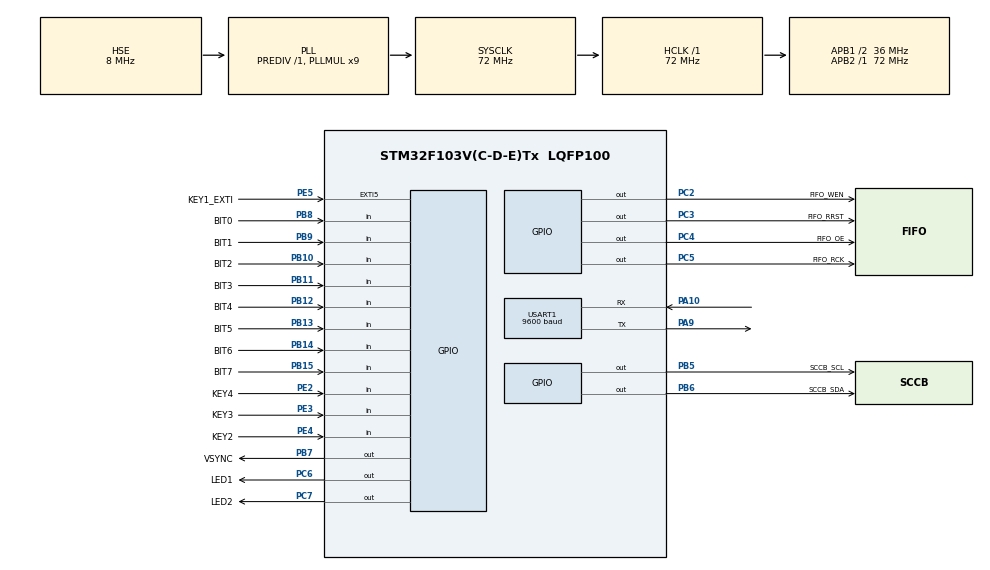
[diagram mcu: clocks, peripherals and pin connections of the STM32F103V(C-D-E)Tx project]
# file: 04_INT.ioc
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Mcu.Family=STM32F1
Mcu.Name=STM32F103V(C-D-E)Tx
Mcu.Package=LQFP100
NVIC.EXTI9_5_IRQn=true\:1\:0\:true\:false\:true\:true
NVIC.PriorityGroup=NVIC_PRIORITYGROUP_4
OSC_IN.Mode=HSE-External-Oscillator
OSC_IN.Signal=RCC_OSC_IN
OSC_OUT.Mode=HSE-External-Oscillator
OSC_OUT.Signal=RCC_OSC_OUT
PA10.Mode=Asynchronous
PA10.Signal=USART1_RX
PA9.Mode=Asynchronous
PA9.Signal=USART1_TX
PB10.GPIO_Label=BIT2
PB10.Signal=GPIO_Input
PB11.GPIO_Label=BIT3
PB11.Signal=GPIO_Input
PB12.GPIO_Label=BIT4
PB12.Signal=GPIO_Input
PB13.GPIO_Label=BIT5
PB13.Signal=GPIO_Input
PB14.GPIO_Label=BIT6
PB14.Signal=GPIO_Input
PB15.GPIO_Label=BIT7
PB15.Signal=GPIO_Input
PB5.GPIO_Label=SCCB_SCL
PB5.GPIO_PuPd=GPIO_PULLUP
PB5.GPIO_Speed=GPIO_SPEED_FREQ_HIGH
PB5.PinState=GPIO_PIN_SET
PB5.Signal=GPIO_Output
PB6.GPIO_Label=SCCB_SDA
PB6.GPIO_PuPd=GPIO_PULLUP
PB6.GPIO_Speed=GPIO_SPEED_FREQ_HIGH
PB6.PinState=GPIO_PIN_SET
PB6.Signal=GPIO_Output
PB7.GPIO_Label=VSYNC
PB7.GPIO_Speed=GPIO_SPEED_FREQ_HIGH
PB7.Signal=GPIO_Output
PB8.GPIO_Label=BIT0
PB8.Signal=GPIO_Input
PB9.GPIO_Label=BIT1
PB9.Signal=GPIO_Input
PC2.GPIO_Label=FIFO_WEN
PC2.GPIO_Speed=GPIO_SPEED_FREQ_HIGH
PC2.Signal=GPIO_Output
PC3.GPIO_Label=FIFO_RRST
PC3.Signal=GPIO_Output
PC4.GPIO_Label=FIFO_OE
PC4.GPIO_Speed=GPIO_SPEED_FREQ_HIGH
PC4.Signal=GPIO_Output
PC5.GPIO_Label=FIFO_RCK
PC5.GPIO_Speed=GPIO_SPEED_FREQ_HIGH
PC5.Signal=GPIO_Output
PC6.GPIO_Label=LED1
PC6.GPIO_Speed=GPIO_SPEED_FREQ_HIGH
PC6.Signal=GPIO_Output
PC7.GPIO_Label=LED2
PC7.GPIO_ModeDefaultOutputPP=GPIO_MODE_OUTPUT_PP
PC7.GPIO_Speed=GPIO_SPEED_FREQ_HIGH
PC7.Signal=GPIO_Output
PE2.GPIO_Label=KEY4
PE2.Signal=GPIO_Input
PE3.GPIO_Label=KEY3
PE3.Signal=GPIO_Input
PE4.GPIO_Label=KEY2
PE4.Signal=GPIO_Input
PE5.GPIO_Label=KEY1_EXTI
PE5.GPIO_ModeDefaultEXTI=GPIO_MODE_IT_FALLING
PE5.Signal=GPXTI5
ProjectManager.HeapSize=0x200
ProjectManager.StackSize=0x400
ProjectManager.TargetToolchain=SW4STM32
RCC.AHBFreq_Value=72000000
RCC.APB1CLKDivider=RCC_HCLK_DIV2
RCC.APB1Freq_Value=36000000
RCC.APB1TimFreq_Value=72000000
RCC.APB2Freq_Value=72000000
RCC.APB2TimFreq_Value=72000000
RCC.HCLKFreq_Value=72000000
RCC.PLLMUL=RCC_PLL_MUL9
RCC.PLLSourceVirtual=RCC_PLLSOURCE_HSE
RCC.SYSCLKFreq_VALUE=72000000
RCC.SYSCLKSource=RCC_SYSCLKSOURCE_PLLCLK
RCC.USBFreq_Value=72000000
USART1.BaudRate=9600
USART1.VirtualMode=VM_ASYNC
VP_SYS_VS_ND.Mode=No_Debug
board=custom

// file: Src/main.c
/* USER CODE BEGIN Header */
/**
  ******************************************************************************
  * @file           : main.c
  * @brief          : Main program body
  ******************************************************************************
  ** This notice applies to any and all portions of this file
  * that are not between comment pairs USER CODE BEGIN and
  * USER CODE END. Other portions of this file, whether
  * inserted by the user or by software development tools
  * are owned by their respective copyright owners.
  *
  * COPYRIGHT(c) 2018 STMicroelectronics
  *
  * Redistribution and use in source and binary forms, with or without modification,
  * are permitted provided that the following conditions are met:
  *   1. Redistributions of source code must retain the above copyright notice,
  *      this list of conditions and the following disclaimer.
  *   2. Redistributions in binary form must reproduce the above copyright notice,
  *      this list of conditions and the following disclaimer in the documentation
  *      and/or other materials provided with the distribution.
  *   3. Neither the name of STMicroelectronics nor the names of its contributors
  *      may be used to endorse or promote products derived from this software
  *      without specific prior written permission.
  *
  * THIS SOFTWARE IS PROVIDED BY THE COPYRIGHT HOLDERS AND CONTRIBUTORS "AS IS"
  * AND ANY EXPRESS OR IMPLIED WARRANTIES, INCLUDING, BUT NOT LIMITED TO, THE
  * IMPLIED WARRANTIES OF MERCHANTABILITY AND FITNESS FOR A PARTICULAR PURPOSE ARE
  * DISCLAIMED. IN NO EVENT SHALL THE COPYRIGHT HOLDER OR CONTRIBUTORS BE LIABLE
  * FOR ANY DIRECT, INDIRECT, INCIDENTAL, SPECIAL, EXEMPLARY, OR CONSEQUENTIAL
  * DAMAGES (INCLUDING, BUT NOT LIMITED TO, PROCUREMENT OF SUBSTITUTE GOODS OR
  * SERVICES; LOSS OF USE, DATA, OR PROFITS; OR BUSINESS INTERRUPTION) HOWEVER
  * CAUSED AND ON ANY THEORY OF LIABILITY, WHETHER IN CONTRACT, STRICT LIABILITY,
  * OR TORT (INCLUDING NEGLIGENCE OR OTHERWISE) ARISING IN ANY WAY OUT OF THE USE
  * OF THIS SOFTWARE, EVEN IF ADVISED OF THE POSSIBILITY OF SUCH DAMAGE.
  *
  ******************************************************************************
  */
/* USER CODE END Header */

#include "main.h"
#include "usart.h"
#include "gpio.h"

/* USER CODE BEGIN Includes */
#include <string.h>
/* USER CODE END Includes */

void SystemClock_Config(void);

int main(void)
{

  /* MCU Configuration--------------------------------------------------------*/

  /* Reset of all peripherals, Initializes the Flash interface and the Systick. */
  HAL_Init();

  /* Configure the system clock */
  SystemClock_Config();

  /* Initialize all configured peripherals */
  MX_GPIO_Init();
  MX_USART1_UART_Init();

  /* Infinite loop */
  while (1)
  {
    /* USER CODE BEGIN 3 */
    HAL_GPIO_TogglePin(LED2_GPIO_Port, LED2_Pin);
    HAL_Delay(500);
  }
  /* USER CODE END 3 */
}

void SystemClock_Config(void)
{
  RCC_OscInitTypeDef RCC_OscInitStruct = {0};
  RCC_ClkInitTypeDef RCC_ClkInitStruct = {0};

  /**Initializes the CPU, AHB and APB busses clocks
  */
  RCC_OscInitStruct.OscillatorType = RCC_OSCILLATORTYPE_HSE;
  RCC_OscInitStruct.HSEState = RCC_HSE_ON;
  RCC_OscInitStruct.HSEPredivValue = RCC_HSE_PREDIV_DIV1;
  RCC_OscInitStruct.HSIState = RCC_HSI_ON;
  RCC_OscInitStruct.PLL.PLLState = RCC_PLL_ON;
  RCC_OscInitStruct.PLL.PLLSource = RCC_PLLSOURCE_HSE;
  RCC_OscInitStruct.PLL.PLLMUL = RCC_PLL_MUL9;
  if (HAL_RCC_OscConfig(&RCC_OscInitStruct) != HAL_OK)
  {
    Error_Handler();
  }
  /**Initializes the CPU, AHB and APB busses clocks
  */
  RCC_ClkInitStruct.ClockType = RCC_CLOCKTYPE_HCLK|RCC_CLOCKTYPE_SYSCLK
                              |RCC_CLOCKTYPE_PCLK1|RCC_CLOCKTYPE_PCLK2;
  RCC_ClkInitStruct.SYSCLKSource = RCC_SYSCLKSOURCE_PLLCLK;
  RCC_ClkInitStruct.AHBCLKDivider = RCC_SYSCLK_DIV1;
  RCC_ClkInitStruct.APB1CLKDivider = RCC_HCLK_DIV2;
  RCC_ClkInitStruct.APB2CLKDivider = RCC_HCLK_DIV1;

  if (HAL_RCC_ClockConfig(&RCC_ClkInitStruct, FLASH_LATENCY_2) != HAL_OK)
  {
    Error_Handler();
  }
}

/* USER CODE BEGIN 4 */
void HAL_GPIO_EXTI_Callback(uint16_t GPIO_Pin)
{
  if(__HAL_GPIO_EXTI_GET_FLAG(KEY1_EXTI_Pin))
  {
    HAL_Delay(20);
    if(HAL_GPIO_ReadPin(KEY1_EXTI_GPIO_Port, KEY1_EXTI_Pin) == 1)  // if KEY1 is released
    {
      HAL_UART_Transmit(&huart1, (uint8_t *) "KEY1 INT\t", strlen("KEY1 INT\t"), 10);
      HAL_GPIO_TogglePin(LED1_GPIO_Port, LED1_Pin);
    }
  }
}
/* USER CODE END 4 */

void Error_Handler(void)
{
}

/************************ (C) COPYRIGHT STMicroelectronics *****END OF FILE****/
